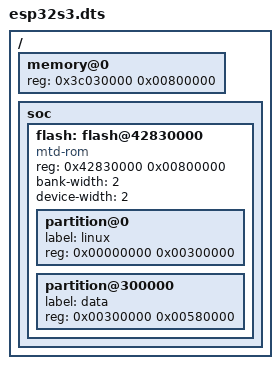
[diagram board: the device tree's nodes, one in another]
// SPDX-License-Identifier: GPL-2.0
/dts-v1/;
#include "esp32s3.dtsi"

/ {
	memory@0 {
		device_type = "memory";
		reg = <0x3c030000 0x00800000>;
	};

	soc {
		flash: flash@42830000 {
			#address-cells = <1>;
			#size-cells = <1>;
			compatible = "mtd-rom";
			reg = <0x42830000 0x00800000>;
			bank-width = <2>;
			device-width = <2>;
			partition@0 {
				label = "linux";
				reg = <0x00000000 0x00300000>;
			};
			partition@300000 {
				label = "data";
				reg = <0x00300000 0x00580000>;
			};
		};
	};
};
